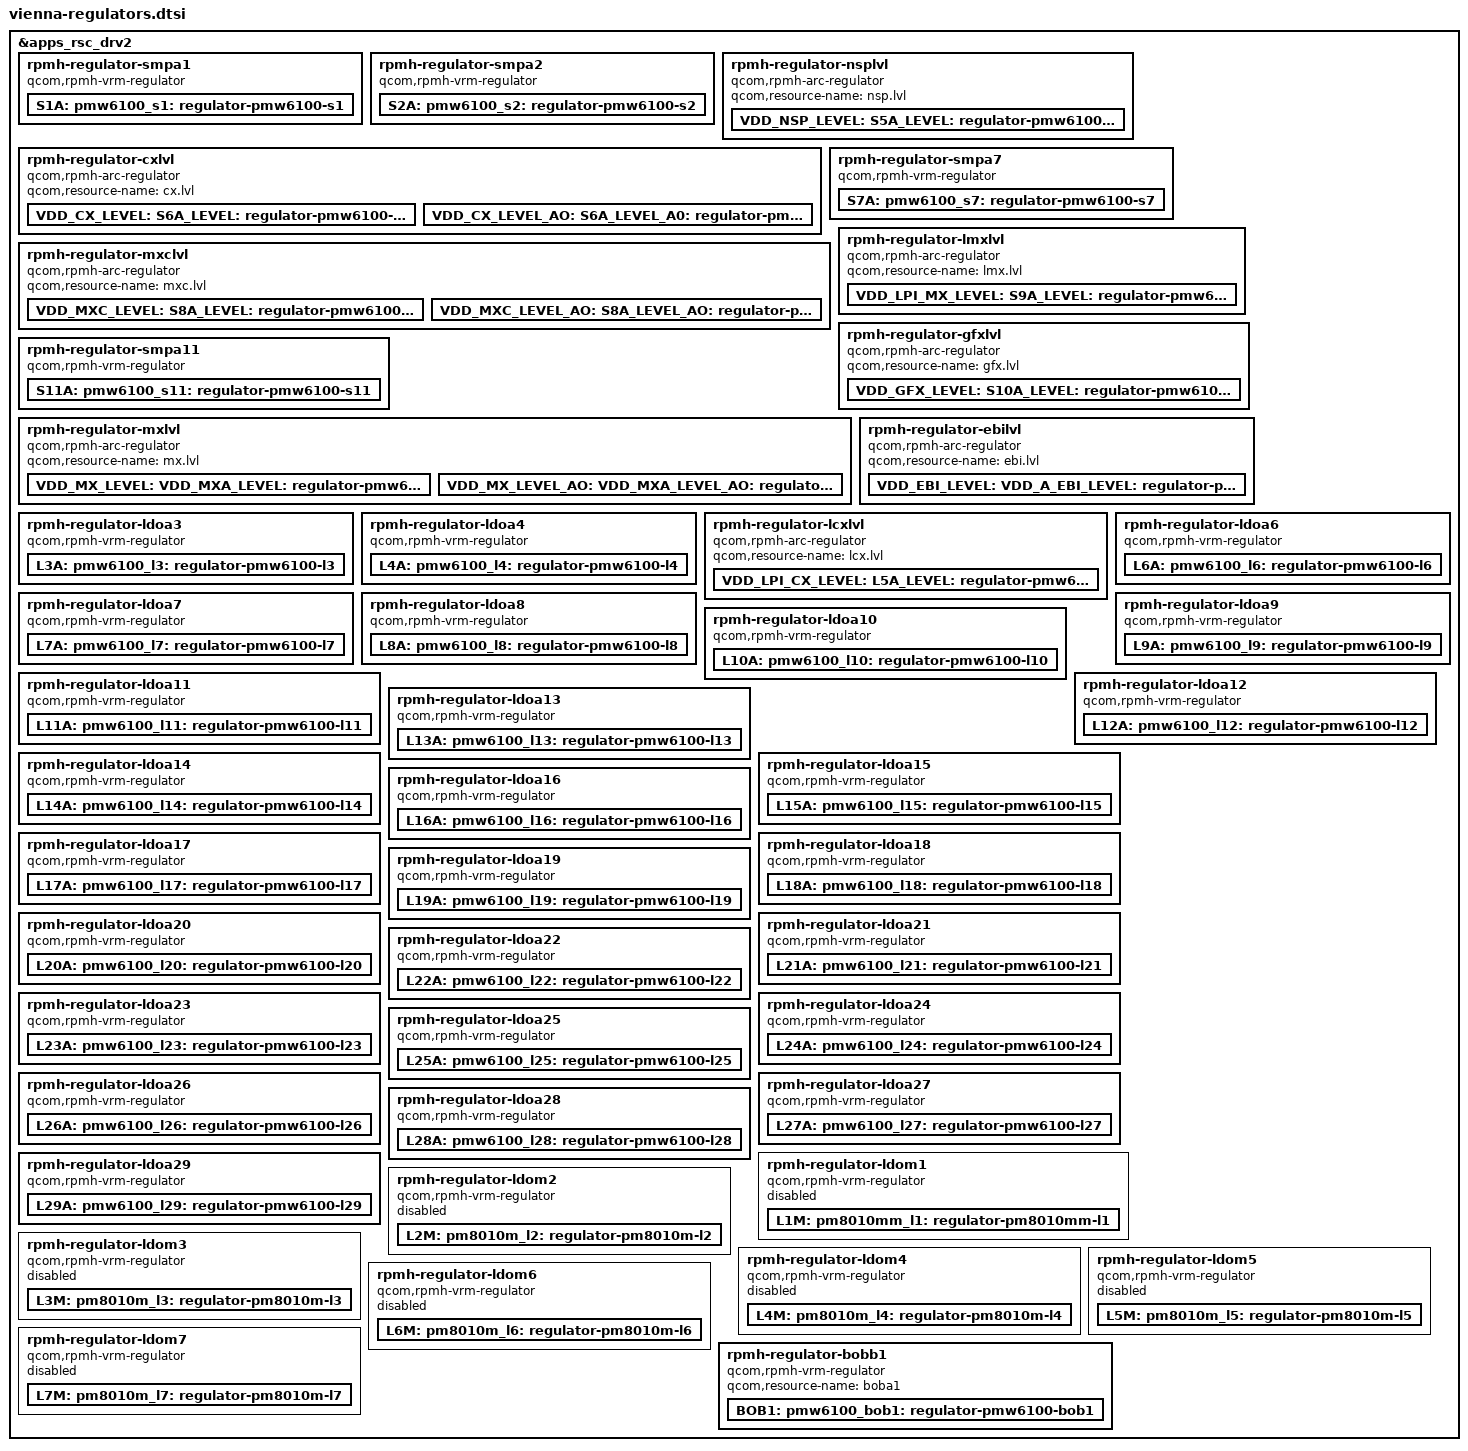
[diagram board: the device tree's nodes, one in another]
// SPDX-License-Identifier: BSD-3-Clause
/*
 * Copyright (c) 2025 Qualcomm Innovation Center, Inc. All rights reserved.
 */

#include <dt-bindings/regulator/qcom,rpmh-regulator-levels.h>

&apps_rsc_drv2 {
	rpmh-regulator-smpa1 {
		compatible = "qcom,rpmh-vrm-regulator";
		qcom,resource-name = "smpa1";
		qcom,regulator-type = "pmic7-ftsmps";
		qcom,supported-modes = <RPMH_REGULATOR_MODE_RET
			RPMH_REGULATOR_MODE_HPM >;
		qcom,mode-threshold-currents = <0 20000>;
		S1A:
		pmw6100_s1: regulator-pmw6100-s1 {
			regulator-name = "pmw6100_s1";
			qcom,set = <RPMH_REGULATOR_SET_ALL>;
			regulator-min-microvolt = <320000>;
			regulator-max-microvolt = <1904000>;
			qcom,init-voltage = <320000>;
		};
	};

	rpmh-regulator-smpa2 {
		compatible = "qcom,rpmh-vrm-regulator";
		qcom,resource-name = "smpa2";
		qcom,regulator-type = "pmic7-ftsmps";
		qcom,supported-modes = <RPMH_REGULATOR_MODE_RET
		RPMH_REGULATOR_MODE_HPM>;
		qcom,mode-threshold-currents = <0 200000>;
		S2A:
		pmw6100_s2: regulator-pmw6100-s2 {
			regulator-name = "pmw6100_s2_level";
			qcom,set = <RPMH_REGULATOR_SET_ALL>;
			regulator-min-microvolt = <870000>;
			regulator-max-microvolt = <1120000>;
			qcom,init-voltage = <870000>;
			qcom,init-mode = <RPMH_REGULATOR_MODE_HPM>;
		};
	};

	rpmh-regulator-nsplvl {
		compatible = "qcom,rpmh-arc-regulator";
		qcom,resource-name = "nsp.lvl";
		VDD_NSP_LEVEL:
		S5A_LEVEL:
		pmw6100_s5_level: regulator-pmw6100-s5-level {
			regulator-name = "pmw6100_s5_level";
			qcom,set = <RPMH_REGULATOR_SET_ALL>;
			regulator-min-microvolt =
				<RPMH_REGULATOR_LEVEL_RETENTION>;
			regulator-max-microvolt = <RPMH_REGULATOR_LEVEL_MAX>;
			qcom,init-voltage-level =
				<RPMH_REGULATOR_LEVEL_RETENTION>;
		};
	};

	rpmh-regulator-cxlvl {
		compatible = "qcom,rpmh-arc-regulator";
		qcom,resource-name = "cx.lvl";
		VDD_CX_LEVEL:
		S6A_LEVEL:
		pmw6100_s6_level: regulator-pmw6100-s6-level {
			regulator-name = "pmw6100_s6_level";
			qcom,set = <RPMH_REGULATOR_SET_ALL>;
			regulator-min-microvolt =
				<RPMH_REGULATOR_LEVEL_RETENTION>;
			regulator-max-microvolt = <RPMH_REGULATOR_LEVEL_MAX>;
			qcom,init-voltage-level =
				<RPMH_REGULATOR_LEVEL_TURBO>;
			proxy-supply = <&VDD_CX_LEVEL>;
			qcom,proxy-consumer-enable;
			qcom,proxy-consumer-voltage =
				<RPMH_REGULATOR_LEVEL_TURBO
				RPMH_REGULATOR_LEVEL_MAX>;
		};

		VDD_CX_LEVEL_AO:
		S6A_LEVEL_A0:
		pmw6100_s6_level_ao: regulator-pmw6100-s6-level-ao {
			regulator-name = "pmw6100_s6_level_ao";
			qcom,set = <RPMH_REGULATOR_SET_ACTIVE>;
			regulator-min-microvolt =
				<RPMH_REGULATOR_LEVEL_RETENTION>;
			regulator-max-microvolt =
				<RPMH_REGULATOR_LEVEL_MAX>;
			qcom,init-voltage-level =
				<RPMH_REGULATOR_LEVEL_RETENTION>;
		};
	};

	rpmh-regulator-smpa7 {
		compatible = "qcom,rpmh-vrm-regulator";
		qcom,resource-name = "smpa7";
		qcom,regulator-type = "pmic7-ftsmps";
		qcom,supported-modes = <RPMH_REGULATOR_MODE_RET
			RPMH_REGULATOR_MODE_HPM>;
		qcom,mode-threshold-currents = <0 20000>;
		S7A:
		pmw6100_s7: regulator-pmw6100-s7 {
			regulator-name = "pmw6100_s7";
			qcom,set = <RPMH_REGULATOR_SET_ALL>;
			regulator-min-microvolt = <320000>;
			regulator-max-microvolt = <960000>;
			qcom,init-voltage = <320000>;
		};
	};

	rpmh-regulator-mxclvl {
		compatible = "qcom,rpmh-arc-regulator";
		qcom,resource-name = "mxc.lvl";
		VDD_MXC_LEVEL:
		S8A_LEVEL:
		pmw6100_s8_level: regulator-pmw6100-s8-level {
			regulator-name = "pmw6100_s8_level";
			qcom,set = <RPMH_REGULATOR_SET_ALL>;
			regulator-min-microvolt =
				<RPMH_REGULATOR_LEVEL_RETENTION>;
			regulator-max-microvolt = <RPMH_REGULATOR_LEVEL_MAX>;
			qcom,init-voltage-level =
				<RPMH_REGULATOR_LEVEL_TURBO>;
			proxy-supply = <&VDD_MXC_LEVEL>;
			qcom,proxy-consumer-enable;
			qcom,proxy-consumer-voltage =
				<RPMH_REGULATOR_LEVEL_TURBO
				RPMH_REGULATOR_LEVEL_MAX>;
		};

		VDD_MXC_LEVEL_AO:
		S8A_LEVEL_AO:
		pmw6100_s8_level_ao: regulator-pmw6100-s8-level-ao {
			regulator-name = "pmw6100_s8_level_ao";
			qcom,set = <RPMH_REGULATOR_SET_ACTIVE>;
			regulator-min-microvolt =
				<RPMH_REGULATOR_LEVEL_RETENTION>;
			regulator-max-microvolt = <RPMH_REGULATOR_LEVEL_MAX>;
			qcom,init-voltage-level =
				<RPMH_REGULATOR_LEVEL_RETENTION>;
		};
	};

	rpmh-regulator-lmxlvl {
		compatible = "qcom,rpmh-arc-regulator";
		qcom,resource-name = "lmx.lvl";
		VDD_LPI_MX_LEVEL:
		S9A_LEVEL:
		pmw6100_s9_level: regulator-pmw6100-s9-level {
			regulator-name = "pmw6100_s9_level";
			qcom,set = <RPMH_REGULATOR_SET_ALL>;
			regulator-min-microvolt =
				<RPMH_REGULATOR_LEVEL_RETENTION>;
			regulator-max-microvolt = <RPMH_REGULATOR_LEVEL_MAX>;
			qcom,init-voltage-level =
				<RPMH_REGULATOR_LEVEL_RETENTION>;
		};
	};

	rpmh-regulator-gfxlvl {
		compatible = "qcom,rpmh-arc-regulator";
		qcom,resource-name = "gfx.lvl";
		VDD_GFX_LEVEL:
		S10A_LEVEL:
		pmw6100_s10_level: regulator-pmw6100-s10-level {
			regulator-name = "pmw6100_s10_level";
			qcom,set = <RPMH_REGULATOR_SET_ALL>;
			regulator-min-microvolt =
				<RPMH_REGULATOR_LEVEL_RETENTION>;
			regulator-max-microvolt = <RPMH_REGULATOR_LEVEL_MAX>;
			qcom,init-voltage-level =
				<RPMH_REGULATOR_LEVEL_RETENTION>;
		};
	};

	rpmh-regulator-smpa11 {
		compatible = "qcom,rpmh-vrm-regulator";
		qcom,resource-name = "smpa11";
		qcom,regulator-type = "pmic7-ftsmps";
		qcom,supported-modes = <RPMH_REGULATOR_MODE_RET
			 RPMH_REGULATOR_MODE_HPM>;
		qcom,mode-threshold-currents = <0 20000>;
		S11A:
		pmw6100_s11: regulator-pmw6100-s11 {
			regulator-name = "pmw6100_s11";
			qcom,set = <RPMH_REGULATOR_SET_ALL>;
			regulator-min-microvolt = <510000>;
			regulator-max-microvolt = <1372000>;
			qcom,init-voltage = <510000>;
		};
	};

	rpmh-regulator-mxlvl {
		compatible = "qcom,rpmh-arc-regulator";
		qcom,resource-name = "mx.lvl";
		VDD_MX_LEVEL: VDD_MXA_LEVEL:
		L1A_LEVEL:
		pmw6100_l1_level: regulator-pmw6100-l1-level {
			regulator-name = "pmw6100_l1_level";
			qcom,set = <RPMH_REGULATOR_SET_ALL>;
			regulator-min-microvolt =
				<RPMH_REGULATOR_LEVEL_RETENTION>;
			regulator-max-microvolt = <RPMH_REGULATOR_LEVEL_MAX>;
			qcom,init-voltage-level =
				<RPMH_REGULATOR_LEVEL_TURBO>;
			proxy-supply = <&VDD_MXA_LEVEL>;
			qcom,proxy-consumer-enable;
			qcom,proxy-consumer-voltage =
				<RPMH_REGULATOR_LEVEL_TURBO
				RPMH_REGULATOR_LEVEL_MAX>;
		};

		VDD_MX_LEVEL_AO: VDD_MXA_LEVEL_AO:
		L1A_LEVEL_AO:
		pmw6100_l1_level_ao: regulator-pmw6100-l1-level-ao {
			regulator-name = "pmw6100_l1_level_ao";
			qcom,set = <RPMH_REGULATOR_SET_ACTIVE>;
			regulator-min-microvolt =
				<RPMH_REGULATOR_LEVEL_RETENTION>;
			regulator-max-microvolt = <RPMH_REGULATOR_LEVEL_MAX>;
			qcom,init-voltage-level =
				<RPMH_REGULATOR_LEVEL_RETENTION>;
		};
	};

	rpmh-regulator-ebilvl {
		compatible = "qcom,rpmh-arc-regulator";
		qcom,resource-name = "ebi.lvl";
		VDD_EBI_LEVEL: VDD_A_EBI_LEVEL:
		L2A_LEVEL:
		pmw6100_l2_level: regulator-pmw6100-l2-level {
			regulator-name = "pmw6100_l2_level";
			qcom,set = <RPMH_REGULATOR_SET_ALL>;
			regulator-min-microvolt =
				<RPMH_REGULATOR_LEVEL_RETENTION>;
			regulator-max-microvolt = <RPMH_REGULATOR_LEVEL_MAX>;
			qcom,init-voltage-level =
				<RPMH_REGULATOR_LEVEL_RETENTION>;
		};
	};

	rpmh-regulator-ldoa3 {
		compatible = "qcom,rpmh-vrm-regulator";
		qcom,resource-name = "ldoa3";
		qcom,regulator-type = "pmic7-ldo";
		qcom,supported-modes =
			<RPMH_REGULATOR_MODE_LPM
			RPMH_REGULATOR_MODE_HPM>;
		qcom,mode-threshold-currents = <0 30000>;

		L3A:
		pmw6100_l3: regulator-pmw6100-l3 {
			regulator-name = "pmw6100_l3";
			qcom,set = <RPMH_REGULATOR_SET_ALL>;
			regulator-min-microvolt = <320000>;
			regulator-max-microvolt = <570000>;
			qcom,init-voltage = <320000>;
			qcom,init-mode = <RPMH_REGULATOR_MODE_HPM>;
		};
	};

	rpmh-regulator-ldoa4 {
		compatible = "qcom,rpmh-vrm-regulator";
		qcom,resource-name = "ldoa4";
		qcom,regulator-type = "pmic7-ldo";
		qcom,supported-modes =
			<RPMH_REGULATOR_MODE_LPM
			RPMH_REGULATOR_MODE_HPM>;
		qcom,mode-threshold-currents = <0 30000>;

		L4A:
		pmw6100_l4: regulator-pmw6100-l4 {
			regulator-name = "pmw6100_l4";
			qcom,set = <RPMH_REGULATOR_SET_ALL>;
			regulator-min-microvolt = <751000>;
			regulator-max-microvolt = <824000>;
			qcom,init-voltage = <751000>;
			qcom,init-mode = <RPMH_REGULATOR_MODE_HPM>;
		};
	};

	rpmh-regulator-lcxlvl {
		compatible = "qcom,rpmh-arc-regulator";
		qcom,resource-name = "lcx.lvl";
		VDD_LPI_CX_LEVEL:
		L5A_LEVEL:
		pmw6100_l5_level: regulator-pmw6100-l5-level {
			regulator-name = "pmw6100_l5_level";
			qcom,set = <RPMH_REGULATOR_SET_ALL>;
			regulator-min-microvolt =
				<RPMH_REGULATOR_LEVEL_RETENTION>;
			regulator-max-microvolt = <RPMH_REGULATOR_LEVEL_MAX>;
			qcom,init-voltage-level =
				<RPMH_REGULATOR_LEVEL_RETENTION>;
		};
	};

	rpmh-regulator-ldoa6 {
		compatible = "qcom,rpmh-vrm-regulator";
		qcom,resource-name = "ldoa6";
		qcom,regulator-type = "pmic7-ldo";
		qcom,supported-modes =
			<RPMH_REGULATOR_MODE_LPM
			RPMH_REGULATOR_MODE_HPM>;
		qcom,mode-threshold-currents = <0 30000>;

		L6A:
		pmw6100_l6: regulator-pmw6100-l6 {
			regulator-name = "pmw6100_l6";
			qcom,set = <RPMH_REGULATOR_SET_ALL>;
			regulator-min-microvolt = <1080000>;
			regulator-max-microvolt = <2000000>;
			qcom,init-voltage = <1080000>;
			qcom,init-mode = <RPMH_REGULATOR_MODE_HPM>;
		};
	};

	rpmh-regulator-ldoa7 {
		compatible = "qcom,rpmh-vrm-regulator";
		qcom,resource-name = "ldoa7";
		qcom,regulator-type = "pmic7-ldo";
		qcom,supported-modes =
			<RPMH_REGULATOR_MODE_LPM
			RPMH_REGULATOR_MODE_HPM>;
		qcom,mode-threshold-currents = <0 30000>;

		L7A:
		pmw6100_l7: regulator-pmw6100-l7 {
			regulator-name = "pmw6100_l7";
			qcom,set = <RPMH_REGULATOR_SET_ALL>;
			regulator-min-microvolt = <1100000>;
			regulator-max-microvolt = <1300000>;
			qcom,init-voltage = <1100000>;
			qcom,init-mode = <RPMH_REGULATOR_MODE_HPM>;
		};
	};

	rpmh-regulator-ldoa8 {
		compatible = "qcom,rpmh-vrm-regulator";
		qcom,resource-name = "ldoa8";
		qcom,regulator-type = "pmic7-ldo";
		qcom,supported-modes =
			<RPMH_REGULATOR_MODE_LPM
			RPMH_REGULATOR_MODE_HPM>;
		qcom,mode-threshold-currents = <0 30000>;

		L8A:
		pmw6100_l8: regulator-pmw6100-l8 {
			regulator-name = "pmw6100_l8";
			qcom,set = <RPMH_REGULATOR_SET_ALL>;
			regulator-min-microvolt = <1080000>;
			regulator-max-microvolt = <2000000>;
			qcom,init-voltage = <1080000>;
			qcom,init-mode = <RPMH_REGULATOR_MODE_HPM>;
		};
	};

	rpmh-regulator-ldoa9 {
		compatible = "qcom,rpmh-vrm-regulator";
		qcom,resource-name = "ldoa9";
		qcom,regulator-type = "pmic5-ldo";
		qcom,supported-modes =
			<RPMH_REGULATOR_MODE_LPM
			RPMH_REGULATOR_MODE_HPM>;
		qcom,mode-threshold-currents = <0 100000>;

		L9A:
		pmw6100_l9: regulator-pmw6100-l9 {
			regulator-name = "pmw6100_l9";
			qcom,set = <RPMH_REGULATOR_SET_ALL>;
			regulator-min-microvolt = <950000>;
			regulator-max-microvolt = <1150000>;
			qcom,init-voltage = <950000>;
			qcom,init-mode = <RPMH_REGULATOR_MODE_HPM>;
		};
	};

	rpmh-regulator-ldoa10 {
		compatible = "qcom,rpmh-vrm-regulator";
		qcom,resource-name = "ldoa10";
		qcom,regulator-type = "pmic7-ldo";
		qcom,supported-modes =
			<RPMH_REGULATOR_MODE_LPM
			RPMH_REGULATOR_MODE_HPM>;
		qcom,mode-threshold-currents = <0 30000>;

		L10A:
		pmw6100_l10: regulator-pmw6100-l10 {
			regulator-name = "pmw6100_l10";
			qcom,set = <RPMH_REGULATOR_SET_ALL>;
			regulator-min-microvolt = <1100000>;
			regulator-max-microvolt = <2000000>;
			qcom,init-voltage = <1100000>;
			qcom,init-mode = <RPMH_REGULATOR_MODE_HPM>;
		};
	};

	rpmh-regulator-ldoa11 {
		compatible = "qcom,rpmh-vrm-regulator";
		qcom,resource-name = "ldoa11";
		qcom,regulator-type = "pmic7-ldo";
		qcom,supported-modes =
			<RPMH_REGULATOR_MODE_LPM
			RPMH_REGULATOR_MODE_HPM>;
		qcom,mode-threshold-currents = <0 30000>;

		L11A:
		pmw6100_l11: regulator-pmw6100-l11 {
			regulator-name = "pmw6100_l11";
			qcom,set = <RPMH_REGULATOR_SET_ALL>;
			regulator-min-microvolt = <1620000>;
			regulator-max-microvolt = <1980000>;
			qcom,init-voltage = <1620000>;
			qcom,init-mode = <RPMH_REGULATOR_MODE_HPM>;
		};
	};

	rpmh-regulator-ldoa12 {
		compatible = "qcom,rpmh-vrm-regulator";
		qcom,resource-name = "ldoa12";
		qcom,regulator-type = "pmic7-ldo";
		qcom,supported-modes =
			<RPMH_REGULATOR_MODE_LPM
			RPMH_REGULATOR_MODE_HPM>;
		qcom,mode-threshold-currents = <0 30000>;

		L12A:
		pmw6100_l12: regulator-pmw6100-l12 {
			regulator-name = "pmw6100_l12";
			qcom,set = <RPMH_REGULATOR_SET_ALL>;
			regulator-min-microvolt = <1700000>;
			regulator-max-microvolt = <1950000>;
			qcom,init-voltage = <1700000>;
			qcom,init-mode = <RPMH_REGULATOR_MODE_HPM>;
		};
	};

	rpmh-regulator-ldoa13 {
		compatible = "qcom,rpmh-vrm-regulator";
		qcom,resource-name = "ldoa13";
		qcom,regulator-type = "pmic7-ldo";
		qcom,supported-modes =
			<RPMH_REGULATOR_MODE_LPM
			RPMH_REGULATOR_MODE_HPM>;
		qcom,mode-threshold-currents = <0 30000>;

		L13A:
		pmw6100_l13: regulator-pmw6100-l13 {
			regulator-name = "pmw6100_l13";
			qcom,set = <RPMH_REGULATOR_SET_ALL>;
			regulator-min-microvolt = <1080000>;
			regulator-max-microvolt = <2000000>;
			qcom,init-voltage = <1080000>;
			qcom,init-mode = <RPMH_REGULATOR_MODE_HPM>;
		};
	};

	rpmh-regulator-ldoa14 {
		compatible = "qcom,rpmh-vrm-regulator";
		qcom,resource-name = "ldoa14";
		qcom,regulator-type = "pmic7-ldo";
		qcom,supported-modes =
			<RPMH_REGULATOR_MODE_LPM
			RPMH_REGULATOR_MODE_HPM>;
		qcom,mode-threshold-currents = <0 30000>;

		L14A:
		pmw6100_l14: regulator-pmw6100-l14 {
			regulator-name = "pmw6100_l14";
			qcom,set = <RPMH_REGULATOR_SET_ALL>;
			regulator-min-microvolt = <1620000>;
			regulator-max-microvolt = <2000000>;
			qcom,init-voltage = <1620000>;
			qcom,init-mode = <RPMH_REGULATOR_MODE_HPM>;
		};
	};

	rpmh-regulator-ldoa15 {
		compatible = "qcom,rpmh-vrm-regulator";
		qcom,resource-name = "ldoa15";
		qcom,regulator-type = "pmic7-ldo";
		qcom,supported-modes =
			<RPMH_REGULATOR_MODE_LPM
			RPMH_REGULATOR_MODE_HPM>;
		qcom,mode-threshold-currents = <0 30000>;

		L15A:
		pmw6100_l15: regulator-pmw6100-l15 {
			regulator-name = "pmw6100_l15";
			qcom,set = <RPMH_REGULATOR_SET_ALL>;
			regulator-min-microvolt = <1650000>;
			regulator-max-microvolt = <1950000>;
			qcom,init-voltage = <1650000>;
			qcom,init-mode = <RPMH_REGULATOR_MODE_HPM>;
		};
	};

	rpmh-regulator-ldoa16 {
		compatible = "qcom,rpmh-vrm-regulator";
		qcom,resource-name = "ldoa16";
		qcom,regulator-type = "pmic7-ldo";
		qcom,supported-modes =
			<RPMH_REGULATOR_MODE_LPM
			RPMH_REGULATOR_MODE_HPM>;
		qcom,mode-threshold-currents = <0 30000>;

		L16A:
		pmw6100_l16: regulator-pmw6100-l16 {
			regulator-name = "pmw6100_l16";
			qcom,set = <RPMH_REGULATOR_SET_ALL>;
			regulator-min-microvolt = <320000>;
			regulator-max-microvolt = <1950000>;
			qcom,init-voltage = <320000>;
			qcom,init-mode = <RPMH_REGULATOR_MODE_HPM>;
		};
	};

	rpmh-regulator-ldoa17 {
		compatible = "qcom,rpmh-vrm-regulator";
		qcom,resource-name = "ldoa17";
		qcom,regulator-type = "pmic7-ldo";
		qcom,supported-modes =
			<RPMH_REGULATOR_MODE_LPM
			RPMH_REGULATOR_MODE_HPM>;
		qcom,mode-threshold-currents = <0 10000>;

		L17A:
		pmw6100_l17: regulator-pmw6100-l17 {
			regulator-name = "pmw6100_l17";
			qcom,set = <RPMH_REGULATOR_SET_ALL>;
			regulator-min-microvolt = <1620000>;
			regulator-max-microvolt = <3544000>;
			qcom,init-voltage = <1620000>;
			qcom,init-mode = <RPMH_REGULATOR_MODE_HPM>;
		};
	};

	rpmh-regulator-ldoa18 {
		compatible = "qcom,rpmh-vrm-regulator";
		qcom,resource-name = "ldoa18";
		qcom,regulator-type = "pmic7-ldo";
		qcom,supported-modes =
			<RPMH_REGULATOR_MODE_LPM
			RPMH_REGULATOR_MODE_HPM>;
		qcom,mode-threshold-currents = <0 30000>;

		L18A:
		pmw6100_l18: regulator-pmw6100-l18 {
			regulator-name = "pmw6100_l18";
			qcom,set = <RPMH_REGULATOR_SET_ALL>;
			regulator-min-microvolt = <1100000>;
			regulator-max-microvolt = <2000000>;
			qcom,init-voltage = <1100000>;
			qcom,init-mode = <RPMH_REGULATOR_MODE_HPM>;
		};
	};

	rpmh-regulator-ldoa19 {
		compatible = "qcom,rpmh-vrm-regulator";
		qcom,resource-name = "ldoa19";
		qcom,regulator-type = "pmic7-ldo";
		qcom,supported-modes =
			<RPMH_REGULATOR_MODE_LPM
			RPMH_REGULATOR_MODE_HPM>;
		qcom,mode-threshold-currents = <0 10000>;

		L19A:
		pmw6100_l19: regulator-pmw6100-l19 {
			regulator-name = "pmw6100_l19";
			qcom,set = <RPMH_REGULATOR_SET_ALL>;
			regulator-min-microvolt = <2700000>;
			regulator-max-microvolt = <3300000>;
			qcom,init-voltage = <2700000>;
			qcom,init-mode = <RPMH_REGULATOR_MODE_HPM>;
		};
	};

	rpmh-regulator-ldoa20 {
		compatible = "qcom,rpmh-vrm-regulator";
		qcom,resource-name = "ldoa20";
		qcom,regulator-type = "pmic7-ldo";
		qcom,supported-modes =
			<RPMH_REGULATOR_MODE_LPM
			RPMH_REGULATOR_MODE_HPM>;
		qcom,mode-threshold-currents = <0 40000>;

		L20A:
		pmw6100_l20: regulator-pmw6100-l20 {
			regulator-name = "pmw6100_l20";
			qcom,set = <RPMH_REGULATOR_SET_ALL>;
			regulator-min-microvolt = <2700000>;
			regulator-max-microvolt = <3544000>;
			qcom,init-voltage = <2700000>;
			qcom,init-mode = <RPMH_REGULATOR_MODE_HPM>;
		};
	};

	rpmh-regulator-ldoa21 {
		compatible = "qcom,rpmh-vrm-regulator";
		qcom,resource-name = "ldoa21";
		qcom,regulator-type = "pmic7-ldo";
		qcom,supported-modes =
			<RPMH_REGULATOR_MODE_LPM
			RPMH_REGULATOR_MODE_HPM>;
		qcom,mode-threshold-currents = <0 10000>;

		L21A:
		pmw6100_l21: regulator-pmw6100-l21 {
			regulator-name = "pmw6100_l21";
			qcom,set = <RPMH_REGULATOR_SET_ALL>;
			regulator-min-microvolt = <3000000>;
			regulator-max-microvolt = <3544000>;
			qcom,init-voltage = <3000000>;
			qcom,init-mode = <RPMH_REGULATOR_MODE_HPM>;
		};
	};

	rpmh-regulator-ldoa22 {
		compatible = "qcom,rpmh-vrm-regulator";
		qcom,resource-name = "ldoa22";
		qcom,regulator-type = "pmic5-ldo";
		qcom,supported-modes =
			<RPMH_REGULATOR_MODE_LPM
			RPMH_REGULATOR_MODE_HPM>;
		qcom,mode-threshold-currents = <0 10000>;

		L22A:
		pmw6100_l22: regulator-pmw6100-l22 {
			regulator-name = "pmw6100_l22";
			qcom,set = <RPMH_REGULATOR_SET_ALL>;
			regulator-min-microvolt = <3100000>;
			regulator-max-microvolt = <5104000>;
			qcom,init-voltage = <3100000>;
			qcom,init-mode = <RPMH_REGULATOR_MODE_HPM>;
		};
	};

	rpmh-regulator-ldoa23 {
		compatible = "qcom,rpmh-vrm-regulator";
		qcom,resource-name = "ldoa23";
		qcom,regulator-type = "pmic5-ldo";

		L23A:
		pmw6100_l23: regulator-pmw6100-l23 {
			regulator-name = "pmw6100_l23";
			qcom,set = <RPMH_REGULATOR_SET_ALL>;
			regulator-min-microvolt = <2700000>;
			regulator-max-microvolt = <2900000>;
			qcom,init-voltage = <2700000>;
			qcom,init-mode = <RPMH_REGULATOR_MODE_HPM>;
		};
	};

	rpmh-regulator-ldoa24 {
		compatible = "qcom,rpmh-vrm-regulator";
		qcom,resource-name = "ldoa24";
		qcom,regulator-type = "pmic7-ldo";
		qcom,supported-modes =
			<RPMH_REGULATOR_MODE_LPM
			RPMH_REGULATOR_MODE_HPM>;
		qcom,mode-threshold-currents = <0 30000>;

		L24A:
		pmw6100_l24: regulator-pmw6100-l24 {
			regulator-name = "pmw6100_l24";
			qcom,set = <RPMH_REGULATOR_SET_ALL>;
			regulator-min-microvolt = <870000>;
			regulator-max-microvolt = <970000>;
			qcom,init-voltage = <870000>;
			qcom,init-mode = <RPMH_REGULATOR_MODE_HPM>;
		};
	};

	rpmh-regulator-ldoa25 {
		compatible = "qcom,rpmh-vrm-regulator";
		qcom,resource-name = "ldoa25";
		qcom,regulator-type = "pmic7-ldo";
		qcom,supported-modes =
			<RPMH_REGULATOR_MODE_LPM
			RPMH_REGULATOR_MODE_HPM>;
		qcom,mode-threshold-currents = <0 30000>;

		L25A:
		pmw6100_l25: regulator-pmw6100-l25 {
			regulator-name = "pmw6100_l25";
			qcom,set = <RPMH_REGULATOR_SET_ALL>;
			regulator-min-microvolt = <875000>;
			regulator-max-microvolt = <880000>;
			qcom,init-voltage = <875000>;
			qcom,init-mode = <RPMH_REGULATOR_MODE_HPM>;
		};
	};

	rpmh-regulator-ldoa26 {
		compatible = "qcom,rpmh-vrm-regulator";
		qcom,resource-name = "ldoa26";
		qcom,regulator-type = "pmic7-ldo";
		qcom,supported-modes =
			<RPMH_REGULATOR_MODE_LPM
			RPMH_REGULATOR_MODE_HPM>;
		qcom,mode-threshold-currents = <0 30000>;

		L26A:
		pmw6100_l26: regulator-pmw6100-l26 {
			regulator-name = "pmw6100_l26";
			qcom,set = <RPMH_REGULATOR_SET_ALL>;
			regulator-min-microvolt = <1200000>;
			regulator-max-microvolt = <1200000>;
			qcom,init-voltage = <1200000>;
			qcom,init-mode = <RPMH_REGULATOR_MODE_HPM>;
		};
	};

	rpmh-regulator-ldoa27 {
		compatible = "qcom,rpmh-vrm-regulator";
		qcom,resource-name = "ldoa27";
		qcom,regulator-type = "pmic7-ldo";
		qcom,supported-modes =
			<RPMH_REGULATOR_MODE_LPM
			RPMH_REGULATOR_MODE_HPM>;
		qcom,mode-threshold-currents = <0 30000>;

		L27A:
		pmw6100_l27: regulator-pmw6100-l27 {
			regulator-name = "pmw6100_l27";
			qcom,set = <RPMH_REGULATOR_SET_ALL>;
			regulator-min-microvolt = <1100000>;
			regulator-max-microvolt = <2000000>;
			qcom,init-voltage = <1100000>;
			qcom,init-mode = <RPMH_REGULATOR_MODE_HPM>;
		};
	};

	rpmh-regulator-ldoa28 {
		compatible = "qcom,rpmh-vrm-regulator";
		qcom,resource-name = "ldoa28";
		qcom,regulator-type = "pmic7-ldo";
		qcom,supported-modes =
			<RPMH_REGULATOR_MODE_LPM
			RPMH_REGULATOR_MODE_HPM>;
		qcom,mode-threshold-currents = <0 30000>;

		L28A:
		pmw6100_l28: regulator-pmw6100-l28 {
			regulator-name = "pmw6100_l28";
			qcom,set = <RPMH_REGULATOR_SET_ALL>;
			regulator-min-microvolt = <1600000>;
			regulator-max-microvolt = <2000000>;
			qcom,init-voltage = <1600000>;
			qcom,init-mode = <RPMH_REGULATOR_MODE_HPM>;
		};
	};

	rpmh-regulator-ldoa29 {
		compatible = "qcom,rpmh-vrm-regulator";
		qcom,resource-name = "ldoa29";
		qcom,regulator-type = "pmic7-ldo";
		qcom,supported-modes =
			<RPMH_REGULATOR_MODE_LPM
			RPMH_REGULATOR_MODE_HPM>;
		qcom,mode-threshold-currents = <0 30000>;

		L29A:
		pmw6100_l29: regulator-pmw6100-l29 {
			regulator-name = "pmw6100_l29";
			qcom,set = <RPMH_REGULATOR_SET_ALL>;
			regulator-min-microvolt = <1080000>;
			regulator-max-microvolt = <1900000>;
			qcom,init-voltage = <1080000>;
			qcom,init-mode = <RPMH_REGULATOR_MODE_HPM>;
		};
	};

	rpmh-regulator-ldom1 {
		compatible = "qcom,rpmh-vrm-regulator";
		qcom,resource-name = "ldom1";
		qcom,regulator-type = "pmic5-ldo";
		qcom,supported-modes =
			<RPMH_REGULATOR_MODE_LPM
			RPMH_REGULATOR_MODE_HPM>;
		qcom,mode-threshold-currents = <0 30000>;
		status = "disabled";

		L1M:
		pm8010mm_l1: regulator-pm8010mm-l1 {
			regulator-name = "pm8010mm_l1";
			qcom,set = <RPMH_REGULATOR_SET_ALL>;
			regulator-min-microvolt = <950000>;
			regulator-max-microvolt = <1150000>;
			qcom,init-voltage = <950000>;
			qcom,init-mode = <RPMH_REGULATOR_MODE_HPM>;
		};
	};

	rpmh-regulator-ldom2 {
		compatible = "qcom,rpmh-vrm-regulator";
		qcom,resource-name = "ldom2";
		qcom,regulator-type = "pmic5-ldo";
		qcom,supported-modes =
			<RPMH_REGULATOR_MODE_LPM
			RPMH_REGULATOR_MODE_HPM>;
		qcom,mode-threshold-currents = <0 30000>;
		status = "disabled";

		L2M:
		pm8010m_l2: regulator-pm8010m-l2 {
			regulator-name = "pm8010m_l2";
			qcom,set = <RPMH_REGULATOR_SET_ALL>;
			regulator-min-microvolt = <528000>;
			regulator-max-microvolt = <1544000>;
			qcom,init-voltage = <528000>;
			qcom,init-mode = <RPMH_REGULATOR_MODE_HPM>;
		};
	};

	rpmh-regulator-ldom3 {
		compatible = "qcom,rpmh-vrm-regulator";
		qcom,resource-name = "ldom3";
		qcom,regulator-type = "pmic5-ldo";
		qcom,supported-modes =
			<RPMH_REGULATOR_MODE_LPM
			RPMH_REGULATOR_MODE_HPM>;
		qcom,mode-threshold-currents = <0 10000>;
		status = "disabled";

		L3M:
		pm8010m_l3: regulator-pm8010m-l3 {
			regulator-name = "pm8010m_l3";
			qcom,set = <RPMH_REGULATOR_SET_ALL>;
			regulator-min-microvolt = <1792000>;
			regulator-max-microvolt = <2900000>;
			qcom,init-voltage = <1792000>;
			qcom,init-mode = <RPMH_REGULATOR_MODE_HPM>;
		};
	};

	rpmh-regulator-ldom4 {
		compatible = "qcom,rpmh-vrm-regulator";
		qcom,resource-name = "ldom4";
		qcom,regulator-type = "pmic5-ldo";
		qcom,supported-modes =
			<RPMH_REGULATOR_MODE_LPM
			RPMH_REGULATOR_MODE_HPM>;
		qcom,mode-threshold-currents = <0 10000>;
		status = "disabled";

		L4M:
		pm8010m_l4: regulator-pm8010m-l4 {
			regulator-name = "pm8010m_l4";
			qcom,set = <RPMH_REGULATOR_SET_ALL>;
			regulator-min-microvolt = <1792000>;
			regulator-max-microvolt = <3312000>;
			qcom,init-voltage = <1792000>;
			qcom,init-mode = <RPMH_REGULATOR_MODE_HPM>;
		};
	};

	rpmh-regulator-ldom5 {
		compatible = "qcom,rpmh-vrm-regulator";
		qcom,resource-name = "ldom5";
		qcom,regulator-type = "pmic5-ldo";
		qcom,supported-modes =
			<RPMH_REGULATOR_MODE_LPM
			RPMH_REGULATOR_MODE_HPM>;
		qcom,mode-threshold-currents = <0 10000>;
		status = "disabled";

		L5M:
		pm8010m_l5: regulator-pm8010m-l5 {
			regulator-name = "pm8010m_l5";
			qcom,set = <RPMH_REGULATOR_SET_ALL>;
			regulator-min-microvolt = <2700000>;
			regulator-max-microvolt = <2900000>;
			qcom,init-voltage = <2700000>;
			qcom,init-mode = <RPMH_REGULATOR_MODE_HPM>;
		};
	};

	rpmh-regulator-ldom6 {
		compatible = "qcom,rpmh-vrm-regulator";
		qcom,resource-name = "ldom6";
		qcom,regulator-type = "pmic5-ldo";
		qcom,supported-modes =
			<RPMH_REGULATOR_MODE_LPM
			RPMH_REGULATOR_MODE_HPM>;
		qcom,mode-threshold-currents = <0 10000>;
		status = "disabled";

		L6M:
		pm8010m_l6: regulator-pm8010m-l6 {
			regulator-name = "pm8010m_l6";
			qcom,set = <RPMH_REGULATOR_SET_ALL>;
			regulator-min-microvolt = <1792000>;
			regulator-max-microvolt = <3312000>;
			qcom,init-voltage = <1792000>;
			qcom,init-mode = <RPMH_REGULATOR_MODE_HPM>;
		};
	};

	rpmh-regulator-ldom7 {
		compatible = "qcom,rpmh-vrm-regulator";
		qcom,resource-name = "ldom7";
		qcom,regulator-type = "pmic5-ldo";
		qcom,supported-modes =
			<RPMH_REGULATOR_MODE_LPM
			RPMH_REGULATOR_MODE_HPM>;
		qcom,mode-threshold-currents = <0 10000>;
		status = "disabled";

		L7M:
		pm8010m_l7: regulator-pm8010m-l7 {
			regulator-name = "pm8010m_l7";
			qcom,set = <RPMH_REGULATOR_SET_ALL>;
			regulator-min-microvolt = <1504000>;
			regulator-max-microvolt = <3544000>;
			qcom,init-voltage = <1504000>;
			qcom,init-mode = <RPMH_REGULATOR_MODE_HPM>;
		};
	};

	rpmh-regulator-bobb1 {
		compatible = "qcom,rpmh-vrm-regulator";
		qcom,resource-name = "boba1";
		BOB1: pmw6100_bob1: regulator-pmw6100-bob1 {
			regulator-name = "pmw6100_bob1";
			qcom,set = <RPMH_REGULATOR_SET_ALL>;
			regulator-min-microvolt = <1504000>;
			regulator-max-microvolt = <4500000>;
			qcom,init-voltage = <1504000>;
		};
	};
};
